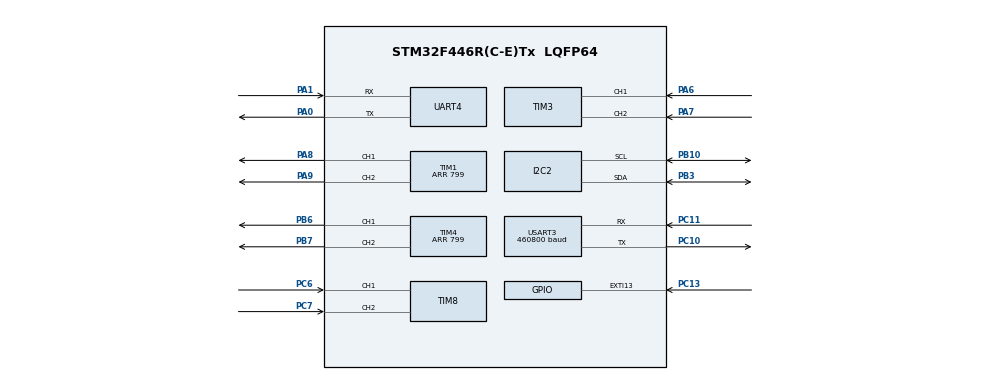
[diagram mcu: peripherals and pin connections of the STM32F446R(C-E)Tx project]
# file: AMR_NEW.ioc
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Dma.Request0=USART3_RX
Dma.USART3_RX.0.Direction=DMA_PERIPH_TO_MEMORY
Dma.USART3_RX.0.FIFOMode=DMA_FIFOMODE_DISABLE
Dma.USART3_RX.0.Instance=DMA1_Stream1
Dma.USART3_RX.0.MemDataAlignment=DMA_MDATAALIGN_BYTE
Dma.USART3_RX.0.MemInc=DMA_MINC_ENABLE
Dma.USART3_RX.0.Mode=DMA_CIRCULAR
Dma.USART3_RX.0.PeriphDataAlignment=DMA_PDATAALIGN_BYTE
Dma.USART3_RX.0.PeriphInc=DMA_PINC_DISABLE
Dma.USART3_RX.0.Priority=DMA_PRIORITY_LOW
FREERTOS.Tasks01=defaultTask,24,128,StartDefaultTask,Default,NULL,Dynamic,NULL,NULL
FREERTOS.configUSE_NEWLIB_REENTRANT=1
Mcu.Family=STM32F4
Mcu.Name=STM32F446R(C-E)Tx
Mcu.Package=LQFP64
NVIC.DMA1_Stream1_IRQn=true\:5\:0\:false\:false\:true\:true\:false\:true\:true
NVIC.EXTI15_10_IRQn=true\:5\:0\:false\:false\:true\:true\:true\:true\:true
NVIC.PriorityGroup=NVIC_PRIORITYGROUP_4
NVIC.TIM6_DAC_IRQn=true\:15\:0\:false\:false\:true\:false\:false\:true\:true
NVIC.TIM7_IRQn=true\:5\:0\:false\:false\:true\:true\:true\:true\:true
NVIC.TimeBase=TIM6_DAC_IRQn
NVIC.TimeBaseIP=TIM6
NVIC.UART4_IRQn=true\:5\:0\:false\:false\:true\:true\:true\:true\:true
PA0-WKUP.Mode=Asynchronous
PA0-WKUP.Signal=UART4_TX
PA1.Mode=Asynchronous
PA1.Signal=UART4_RX
PA13.Mode=Serial_Wire
PA13.Signal=SYS_JTMS-SWDIO
PA14.Mode=Serial_Wire
PA14.Signal=SYS_JTCK-SWCLK
PA6.Signal=S_TIM3_CH1
PA7.Signal=S_TIM3_CH2
PA8.Signal=S_TIM1_CH1
PA9.Signal=S_TIM1_CH2
PB10.Mode=I2C
PB10.Signal=I2C2_SCL
PB3.Mode=I2C
PB3.Signal=I2C2_SDA
PB6.Signal=S_TIM4_CH1
PB7.Signal=S_TIM4_CH2
PC10.Mode=Asynchronous
PC10.Signal=USART3_TX
PC11.Mode=Asynchronous
PC11.Signal=USART3_RX
PC13.Signal=GPXTI13
PC6.Signal=S_TIM8_CH1
PC7.Signal=S_TIM8_CH2
ProjectManager.HeapSize=0x200
ProjectManager.StackSize=0x400
ProjectManager.TargetToolchain=STM32CubeIDE
RCC.CortexFreq_Value=16000000
RCC.USBFreq_Value=96000000
RCC.VCOOutputFreq_Value=192000000
SH.S_TIM1_CH1.0=TIM1_CH1,PWM Generation1 CH1
SH.S_TIM1_CH2.0=TIM1_CH2,PWM Generation2 CH2
SH.S_TIM3_CH1.0=TIM3_CH1,Encoder_Interface
SH.S_TIM3_CH2.0=TIM3_CH2,Encoder_Interface
SH.S_TIM4_CH1.0=TIM4_CH1,PWM Generation1 CH1
SH.S_TIM4_CH2.0=TIM4_CH2,PWM Generation2 CH2
SH.S_TIM8_CH1.0=TIM8_CH1,Encoder_Interface
SH.S_TIM8_CH2.0=TIM8_CH2,Encoder_Interface
TIM1.Channel-PWM\ Generation1\ CH1=TIM_CHANNEL_1
TIM1.Channel-PWM\ Generation2\ CH2=TIM_CHANNEL_2
TIM1.Period=799
TIM3.EncoderMode=TIM_ENCODERMODE_TI12
TIM4.Channel-PWM\ Generation1\ CH1=TIM_CHANNEL_1
TIM4.Channel-PWM\ Generation2\ CH2=TIM_CHANNEL_2
TIM4.Period=799
TIM7.Period=99
TIM7.Prescaler=1599
TIM8.EncoderMode=TIM_ENCODERMODE_TI12
UART4.VirtualMode=Asynchronous
USART3.BaudRate=460800
USART3.VirtualMode=VM_ASYNC
VP_FREERTOS_VS_CMSIS_V2.Mode=CMSIS_V2
VP_SYS_VS_tim6.Mode=TIM6
VP_TIM7_VS_ClockSourceINT.Mode=Enable_Timer
board=custom

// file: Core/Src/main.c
/* USER CODE BEGIN Header */
/**
  ******************************************************************************
  * @file           : main.c
  * @brief          : Main program body
  ******************************************************************************
  * @attention
  *
  * Copyright (c) 2026 STMicroelectronics.
  * All rights reserved.
  *
  * This software is licensed under terms that can be found in the LICENSE file
  * in the root directory of this software component.
  * If no LICENSE file comes with this software, it is provided AS-IS.
  *
  ******************************************************************************
  */
/* USER CODE END Header */
#include "main.h"
#include "cmsis_os.h"

I2C_HandleTypeDef hi2c2;

TIM_HandleTypeDef htim1;
TIM_HandleTypeDef htim3;
TIM_HandleTypeDef htim4;
TIM_HandleTypeDef htim7;
TIM_HandleTypeDef htim8;

UART_HandleTypeDef huart4;
UART_HandleTypeDef huart3;
DMA_HandleTypeDef hdma_usart3_rx;

/* Definitions for defaultTask */
osThreadId_t defaultTaskHandle;
const osThreadAttr_t defaultTask_attributes = {
  .name = "defaultTask",
  .stack_size = 128 * 4,
  .priority = (osPriority_t) osPriorityNormal,
};

void SystemClock_Config(void);
static void MX_GPIO_Init(void);
static void MX_DMA_Init(void);
static void MX_TIM1_Init(void);
static void MX_TIM3_Init(void);
static void MX_TIM4_Init(void);
static void MX_TIM8_Init(void);
static void MX_UART4_Init(void);
static void MX_TIM7_Init(void);
static void MX_I2C2_Init(void);
static void MX_USART3_UART_Init(void);
void StartDefaultTask(void *argument);

/* USER CODE BEGIN PFP */
void CodingDay_Init(void);
void CodingDay_TimerISR(void);

/* USER CODE END PFP */

int main(void)
{

  /* MCU Configuration--------------------------------------------------------*/

  /* Reset of all peripherals, Initializes the Flash interface and the Systick. */
  HAL_Init();

  /* Configure the system clock */
  SystemClock_Config();

  /* Initialize all configured peripherals */
  MX_GPIO_Init();
  MX_DMA_Init();
  MX_TIM1_Init();
  MX_TIM3_Init();
  MX_TIM4_Init();
  MX_TIM8_Init();
  MX_UART4_Init();
  MX_TIM7_Init();
  MX_I2C2_Init();
  MX_USART3_UART_Init();

  /* Init scheduler */
  osKernelInitialize();

  /* Create the thread(s) */
  /* creation of defaultTask */
  defaultTaskHandle = osThreadNew(StartDefaultTask, NULL, &defaultTask_attributes);

  /* USER CODE BEGIN RTOS_THREADS */
  CodingDay_Init();
  /* add threads, ... */
  /* USER CODE END RTOS_THREADS */

  /* Start scheduler */
  osKernelStart();

  /* We should never get here as control is now taken by the scheduler */

  /* Infinite loop */
  while (1)
  {

  }
}

void SystemClock_Config(void)
{
  RCC_OscInitTypeDef RCC_OscInitStruct = {0};
  RCC_ClkInitTypeDef RCC_ClkInitStruct = {0};

  /** Configure the main internal regulator output voltage
  */
  __HAL_RCC_PWR_CLK_ENABLE();
  __HAL_PWR_VOLTAGESCALING_CONFIG(PWR_REGULATOR_VOLTAGE_SCALE3);

  /** Initializes the RCC Oscillators according to the specified parameters
  * in the RCC_OscInitTypeDef structure.
  */
  RCC_OscInitStruct.OscillatorType = RCC_OSCILLATORTYPE_HSI;
  RCC_OscInitStruct.HSIState = RCC_HSI_ON;
  RCC_OscInitStruct.HSICalibrationValue = RCC_HSICALIBRATION_DEFAULT;
  RCC_OscInitStruct.PLL.PLLState = RCC_PLL_NONE;
  if (HAL_RCC_OscConfig(&RCC_OscInitStruct) != HAL_OK)
  {
    Error_Handler();
  }

  /** Initializes the CPU, AHB and APB buses clocks
  */
  RCC_ClkInitStruct.ClockType = RCC_CLOCKTYPE_HCLK|RCC_CLOCKTYPE_SYSCLK
                              |RCC_CLOCKTYPE_PCLK1|RCC_CLOCKTYPE_PCLK2;
  RCC_ClkInitStruct.SYSCLKSource = RCC_SYSCLKSOURCE_HSI;
  RCC_ClkInitStruct.AHBCLKDivider = RCC_SYSCLK_DIV1;
  RCC_ClkInitStruct.APB1CLKDivider = RCC_HCLK_DIV1;
  RCC_ClkInitStruct.APB2CLKDivider = RCC_HCLK_DIV1;

  if (HAL_RCC_ClockConfig(&RCC_ClkInitStruct, FLASH_LATENCY_0) != HAL_OK)
  {
    Error_Handler();
  }
}

static void MX_I2C2_Init(void)
{

  hi2c2.Instance = I2C2;
  hi2c2.Init.ClockSpeed = 100000;
  hi2c2.Init.DutyCycle = I2C_DUTYCYCLE_2;
  hi2c2.Init.OwnAddress1 = 0;
  hi2c2.Init.AddressingMode = I2C_ADDRESSINGMODE_7BIT;
  hi2c2.Init.DualAddressMode = I2C_DUALADDRESS_DISABLE;
  hi2c2.Init.OwnAddress2 = 0;
  hi2c2.Init.GeneralCallMode = I2C_GENERALCALL_DISABLE;
  hi2c2.Init.NoStretchMode = I2C_NOSTRETCH_DISABLE;
  if (HAL_I2C_Init(&hi2c2) != HAL_OK)
  {
    Error_Handler();
  }

}

static void MX_TIM1_Init(void)
{

  TIM_MasterConfigTypeDef sMasterConfig = {0};
  TIM_OC_InitTypeDef sConfigOC = {0};
  TIM_BreakDeadTimeConfigTypeDef sBreakDeadTimeConfig = {0};

  htim1.Instance = TIM1;
  htim1.Init.Prescaler = 0;
  htim1.Init.CounterMode = TIM_COUNTERMODE_UP;
  htim1.Init.Period = 799;
  htim1.Init.ClockDivision = TIM_CLOCKDIVISION_DIV1;
  htim1.Init.RepetitionCounter = 0;
  htim1.Init.AutoReloadPreload = TIM_AUTORELOAD_PRELOAD_DISABLE;
  if (HAL_TIM_PWM_Init(&htim1) != HAL_OK)
  {
    Error_Handler();
  }
  sMasterConfig.MasterOutputTrigger = TIM_TRGO_RESET;
  sMasterConfig.MasterSlaveMode = TIM_MASTERSLAVEMODE_DISABLE;
  if (HAL_TIMEx_MasterConfigSynchronization(&htim1, &sMasterConfig) != HAL_OK)
  {
    Error_Handler();
  }
  sConfigOC.OCMode = TIM_OCMODE_PWM1;
  sConfigOC.Pulse = 0;
  sConfigOC.OCPolarity = TIM_OCPOLARITY_HIGH;
  sConfigOC.OCNPolarity = TIM_OCNPOLARITY_HIGH;
  sConfigOC.OCFastMode = TIM_OCFAST_DISABLE;
  sConfigOC.OCIdleState = TIM_OCIDLESTATE_RESET;
  sConfigOC.OCNIdleState = TIM_OCNIDLESTATE_RESET;
  if (HAL_TIM_PWM_ConfigChannel(&htim1, &sConfigOC, TIM_CHANNEL_1) != HAL_OK)
  {
    Error_Handler();
  }
  if (HAL_TIM_PWM_ConfigChannel(&htim1, &sConfigOC, TIM_CHANNEL_2) != HAL_OK)
  {
    Error_Handler();
  }
  sBreakDeadTimeConfig.OffStateRunMode = TIM_OSSR_DISABLE;
  sBreakDeadTimeConfig.OffStateIDLEMode = TIM_OSSI_DISABLE;
  sBreakDeadTimeConfig.LockLevel = TIM_LOCKLEVEL_OFF;
  sBreakDeadTimeConfig.DeadTime = 0;
  sBreakDeadTimeConfig.BreakState = TIM_BREAK_DISABLE;
  sBreakDeadTimeConfig.BreakPolarity = TIM_BREAKPOLARITY_HIGH;
  sBreakDeadTimeConfig.AutomaticOutput = TIM_AUTOMATICOUTPUT_DISABLE;
  if (HAL_TIMEx_ConfigBreakDeadTime(&htim1, &sBreakDeadTimeConfig) != HAL_OK)
  {
    Error_Handler();
  }
  HAL_TIM_MspPostInit(&htim1);

}

static void MX_TIM3_Init(void)
{

  TIM_Encoder_InitTypeDef sConfig = {0};
  TIM_MasterConfigTypeDef sMasterConfig = {0};

  htim3.Instance = TIM3;
  htim3.Init.Prescaler = 0;
  htim3.Init.CounterMode = TIM_COUNTERMODE_UP;
  htim3.Init.Period = 65535;
  htim3.Init.ClockDivision = TIM_CLOCKDIVISION_DIV1;
  htim3.Init.AutoReloadPreload = TIM_AUTORELOAD_PRELOAD_DISABLE;
  sConfig.EncoderMode = TIM_ENCODERMODE_TI12;
  sConfig.IC1Polarity = TIM_ICPOLARITY_RISING;
  sConfig.IC1Selection = TIM_ICSELECTION_DIRECTTI;
  sConfig.IC1Prescaler = TIM_ICPSC_DIV1;
  sConfig.IC1Filter = 0;
  sConfig.IC2Polarity = TIM_ICPOLARITY_RISING;
  sConfig.IC2Selection = TIM_ICSELECTION_DIRECTTI;
  sConfig.IC2Prescaler = TIM_ICPSC_DIV1;
  sConfig.IC2Filter = 0;
  if (HAL_TIM_Encoder_Init(&htim3, &sConfig) != HAL_OK)
  {
    Error_Handler();
  }
  sMasterConfig.MasterOutputTrigger = TIM_TRGO_RESET;
  sMasterConfig.MasterSlaveMode = TIM_MASTERSLAVEMODE_DISABLE;
  if (HAL_TIMEx_MasterConfigSynchronization(&htim3, &sMasterConfig) != HAL_OK)
  {
    Error_Handler();
  }

}

static void MX_TIM4_Init(void)
{

  TIM_MasterConfigTypeDef sMasterConfig = {0};
  TIM_OC_InitTypeDef sConfigOC = {0};

  htim4.Instance = TIM4;
  htim4.Init.Prescaler = 0;
  htim4.Init.CounterMode = TIM_COUNTERMODE_UP;
  htim4.Init.Period = 799;
  htim4.Init.ClockDivision = TIM_CLOCKDIVISION_DIV1;
  htim4.Init.AutoReloadPreload = TIM_AUTORELOAD_PRELOAD_DISABLE;
  if (HAL_TIM_PWM_Init(&htim4) != HAL_OK)
  {
    Error_Handler();
  }
  sMasterConfig.MasterOutputTrigger = TIM_TRGO_RESET;
  sMasterConfig.MasterSlaveMode = TIM_MASTERSLAVEMODE_DISABLE;
  if (HAL_TIMEx_MasterConfigSynchronization(&htim4, &sMasterConfig) != HAL_OK)
  {
    Error_Handler();
  }
  sConfigOC.OCMode = TIM_OCMODE_PWM1;
  sConfigOC.Pulse = 0;
  sConfigOC.OCPolarity = TIM_OCPOLARITY_HIGH;
  sConfigOC.OCFastMode = TIM_OCFAST_DISABLE;
  if (HAL_TIM_PWM_ConfigChannel(&htim4, &sConfigOC, TIM_CHANNEL_1) != HAL_OK)
  {
    Error_Handler();
  }
  if (HAL_TIM_PWM_ConfigChannel(&htim4, &sConfigOC, TIM_CHANNEL_2) != HAL_OK)
  {
    Error_Handler();
  }
  HAL_TIM_MspPostInit(&htim4);

}

static void MX_TIM7_Init(void)
{

  TIM_MasterConfigTypeDef sMasterConfig = {0};

  htim7.Instance = TIM7;
  htim7.Init.Prescaler = 1599;
  htim7.Init.CounterMode = TIM_COUNTERMODE_UP;
  htim7.Init.Period = 99;
  htim7.Init.AutoReloadPreload = TIM_AUTORELOAD_PRELOAD_DISABLE;
  if (HAL_TIM_Base_Init(&htim7) != HAL_OK)
  {
    Error_Handler();
  }
  sMasterConfig.MasterOutputTrigger = TIM_TRGO_RESET;
  sMasterConfig.MasterSlaveMode = TIM_MASTERSLAVEMODE_DISABLE;
  if (HAL_TIMEx_MasterConfigSynchronization(&htim7, &sMasterConfig) != HAL_OK)
  {
    Error_Handler();
  }

}

static void MX_TIM8_Init(void)
{

  TIM_Encoder_InitTypeDef sConfig = {0};
  TIM_MasterConfigTypeDef sMasterConfig = {0};

  htim8.Instance = TIM8;
  htim8.Init.Prescaler = 0;
  htim8.Init.CounterMode = TIM_COUNTERMODE_UP;
  htim8.Init.Period = 65535;
  htim8.Init.ClockDivision = TIM_CLOCKDIVISION_DIV1;
  htim8.Init.RepetitionCounter = 0;
  htim8.Init.AutoReloadPreload = TIM_AUTORELOAD_PRELOAD_DISABLE;
  sConfig.EncoderMode = TIM_ENCODERMODE_TI12;
  sConfig.IC1Polarity = TIM_ICPOLARITY_RISING;
  sConfig.IC1Selection = TIM_ICSELECTION_DIRECTTI;
  sConfig.IC1Prescaler = TIM_ICPSC_DIV1;
  sConfig.IC1Filter = 0;
  sConfig.IC2Polarity = TIM_ICPOLARITY_RISING;
  sConfig.IC2Selection = TIM_ICSELECTION_DIRECTTI;
  sConfig.IC2Prescaler = TIM_ICPSC_DIV1;
  sConfig.IC2Filter = 0;
  if (HAL_TIM_Encoder_Init(&htim8, &sConfig) != HAL_OK)
  {
    Error_Handler();
  }
  sMasterConfig.MasterOutputTrigger = TIM_TRGO_RESET;
  sMasterConfig.MasterSlaveMode = TIM_MASTERSLAVEMODE_DISABLE;
  if (HAL_TIMEx_MasterConfigSynchronization(&htim8, &sMasterConfig) != HAL_OK)
  {
    Error_Handler();
  }

}

static void MX_UART4_Init(void)
{

  huart4.Instance = UART4;
  huart4.Init.BaudRate = 115200;
  huart4.Init.WordLength = UART_WORDLENGTH_8B;
  huart4.Init.StopBits = UART_STOPBITS_1;
  huart4.Init.Parity = UART_PARITY_NONE;
  huart4.Init.Mode = UART_MODE_TX_RX;
  huart4.Init.HwFlowCtl = UART_HWCONTROL_NONE;
  huart4.Init.OverSampling = UART_OVERSAMPLING_16;
  if (HAL_UART_Init(&huart4) != HAL_OK)
  {
    Error_Handler();
  }

}

static void MX_USART3_UART_Init(void)
{

  huart3.Instance = USART3;
  huart3.Init.BaudRate = 460800;
  huart3.Init.WordLength = UART_WORDLENGTH_8B;
  huart3.Init.StopBits = UART_STOPBITS_1;
  huart3.Init.Parity = UART_PARITY_NONE;
  huart3.Init.Mode = UART_MODE_TX_RX;
  huart3.Init.HwFlowCtl = UART_HWCONTROL_NONE;
  huart3.Init.OverSampling = UART_OVERSAMPLING_16;
  if (HAL_UART_Init(&huart3) != HAL_OK)
  {
    Error_Handler();
  }

}

static void MX_DMA_Init(void)
{

  /* DMA controller clock enable */
  __HAL_RCC_DMA1_CLK_ENABLE();

  /* DMA interrupt init */
  /* DMA1_Stream1_IRQn interrupt configuration */
  HAL_NVIC_SetPriority(DMA1_Stream1_IRQn, 5, 0);
  HAL_NVIC_EnableIRQ(DMA1_Stream1_IRQn);

}

static void MX_GPIO_Init(void)
{
  GPIO_InitTypeDef GPIO_InitStruct = {0};

  /* GPIO Ports Clock Enable */
  __HAL_RCC_GPIOC_CLK_ENABLE();
  __HAL_RCC_GPIOA_CLK_ENABLE();
  __HAL_RCC_GPIOB_CLK_ENABLE();

  /*Configure GPIO pin : PC13 */
  GPIO_InitStruct.Pin = GPIO_PIN_13;
  GPIO_InitStruct.Mode = GPIO_MODE_IT_RISING;
  GPIO_InitStruct.Pull = GPIO_NOPULL;
  HAL_GPIO_Init(GPIOC, &GPIO_InitStruct);

  /* EXTI interrupt init*/
  HAL_NVIC_SetPriority(EXTI15_10_IRQn, 5, 0);
  HAL_NVIC_EnableIRQ(EXTI15_10_IRQn);

}

void StartDefaultTask(void *argument)
{
  for(;;)
  {
    osDelay(1);
  }
}

void HAL_TIM_PeriodElapsedCallback(TIM_HandleTypeDef *htim)
{
  if (htim->Instance == TIM6) {
    HAL_IncTick();
  }
  /* USER CODE BEGIN Callback 1 */
  if (htim->Instance == TIM7) CodingDay_TimerISR();

  /* USER CODE END Callback 1 */
}

void Error_Handler(void)
{
  __disable_irq();
  while (1)
  {
  }
}
